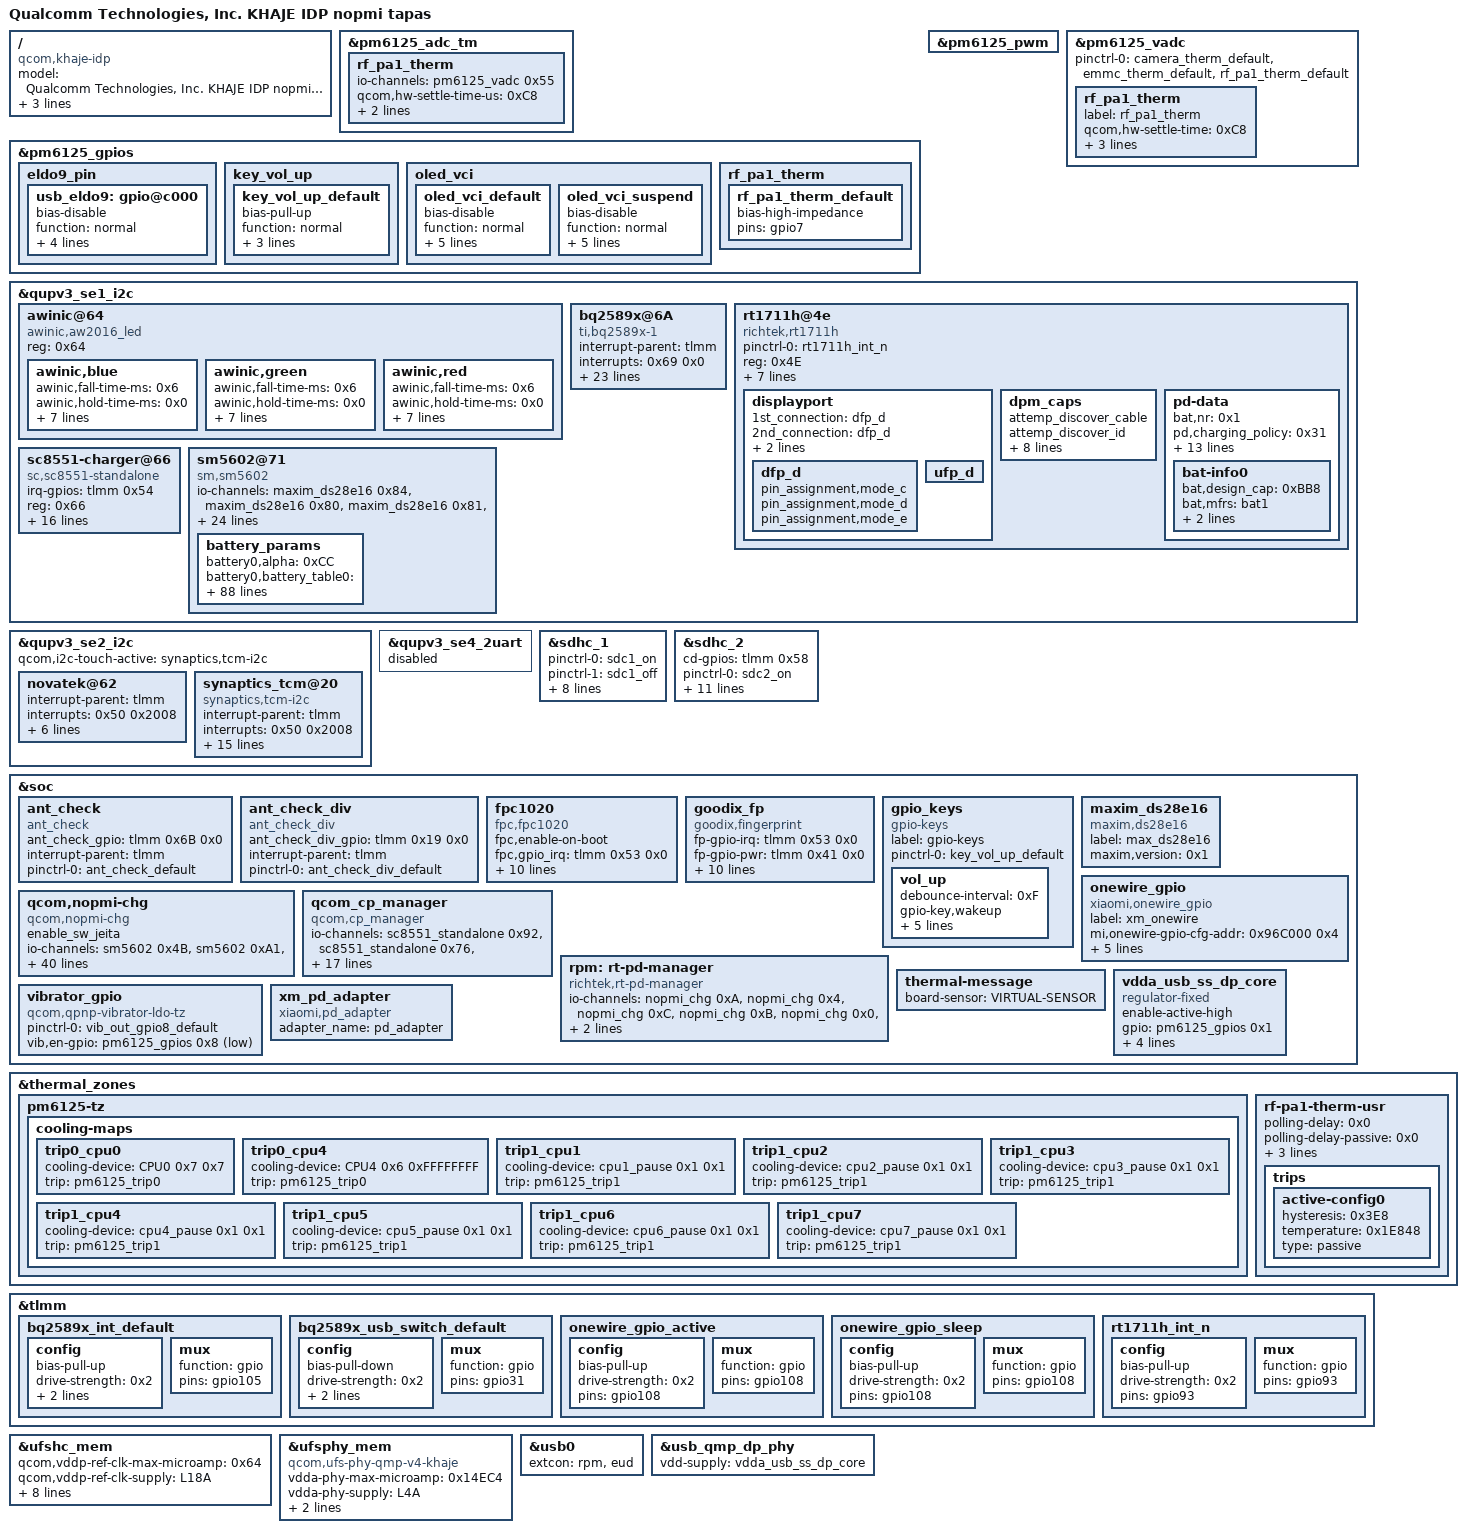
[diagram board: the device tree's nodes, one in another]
/dts-v1/;
// version: 17
// last_comp_version: 16
// boot_cpuid_phys: 0x0

/ {
    compatible = "qcom,khaje-idp", "qcom,khaje", "qcom,idp";
    model = "Qualcomm Technologies, Inc. KHAJE IDP nopmi tapas";
    qcom,board-id = <0x20022 0x0>;
    qcom,msm-id = <0x24A 0x10000>;
    qcom,pmic-id = <0x2D 0x0 0x0 0x0>;
};

&pm6125_adc_tm {
    status = "ok";
    rf_pa1_therm {
        io-channels = <&pm6125_vadc 0x55>;
        qcom,hw-settle-time-us = <0xC8>;
        qcom,ratiometric;
        reg = <0x3>;
    };
};

&pm6125_gpios {
    eldo9_pin {
        usb_eldo9: gpio@c000 {
            bias-disable;
            function = "normal";
            output-high;
            pins = "gpio1";
            power-source = <0x0>;
            qcom,drive-strength = <0x2>;
        };
    };
    key_vol_up {
        key_vol_up_default: key_vol_up_default {
            bias-pull-up;
            function = "normal";
            input-enable;
            pins = "gpio5";
            power-source = <0x0>;
        };
    };
    oled_vci {
        oled_vci_default: oled_vci_default {
            bias-disable;
            function = "normal";
            input-disable;
            output-high;
            pins = "gpio9";
            power-source = <0x0>;
            qcom,drive-strength = <0x2>;
        };
        oled_vci_suspend: oled_vci_suspend {
            bias-disable;
            function = "normal";
            input-disable;
            output-low;
            pins = "gpio9";
            power-source = <0x0>;
            qcom,drive-strength = <0x2>;
        };
    };
    rf_pa1_therm {
        rf_pa1_therm_default: rf_pa1_therm_default {
            bias-high-impedance;
            pins = "gpio7";
        };
    };
};

&pm6125_pwm {
    status = "ok";
};

&pm6125_vadc {
    pinctrl-0 = <&camera_therm_default &emmc_therm_default &rf_pa1_therm_default>;
    rf_pa1_therm {
        label = "rf_pa1_therm";
        qcom,hw-settle-time = <0xC8>;
        qcom,pre-scaling = <0x1 0x1>;
        qcom,ratiometric;
        reg = <0x55>;
    };
};

&qupv3_se1_i2c {
    #address-cells = <0x1>;
    #size-cells = <0x0>;
    status = "ok";
    awinic@64 {
        compatible = "awinic,aw2016_led";
        reg = <0x64>;
        awinic,blue {
            awinic,fall-time-ms = <0x6>;
            awinic,hold-time-ms = <0x0>;
            awinic,id = <0x2>;
            awinic,imax = <0x2>;
            awinic,led-current = <0x3>;
            awinic,max-brightness = <0xFF>;
            awinic,name = "blue";
            awinic,off-time-ms = <0x4>;
            awinic,rise-time-ms = <0x6>;
        };
        awinic,green {
            awinic,fall-time-ms = <0x6>;
            awinic,hold-time-ms = <0x0>;
            awinic,id = <0x1>;
            awinic,imax = <0x2>;
            awinic,led-current = <0x3>;
            awinic,max-brightness = <0xFF>;
            awinic,name = "green";
            awinic,off-time-ms = <0x4>;
            awinic,rise-time-ms = <0x6>;
        };
        awinic,red {
            awinic,fall-time-ms = <0x6>;
            awinic,hold-time-ms = <0x0>;
            awinic,id = <0x0>;
            awinic,imax = <0x2>;
            awinic,led-current = <0x3>;
            awinic,max-brightness = <0xFF>;
            awinic,name = "red";
            awinic,off-time-ms = <0x4>;
            awinic,rise-time-ms = <0x6>;
        };
    };
    bq2589x@6A {
        #address-cells = <0x1>;
        #io-channel-cells = <0x1>;
        #size-cells = <0x0>;
        compatible = "ti,bq2589x-1";
        interrupt-parent = <&tlmm>;
        interrupts = <0x69 0x0>;
        intr-gpio = <&tlmm 0x69 0x0>;
        io-channel-names = "ds_chip_ok", "fastcharge_mode", "fg_monitor_work", "mtbf_cur", "usb_real_type", "pd_active", "typec_cc_orientation", "typec_mode", "ffc_disable";
        io-channels = <&maxim_ds28e16 0x8D &sm5602 0xA4 &sm5602 0xAC &nopmi_chg 0x90 &nopmi_chg 0xA &nopmi_chg 0x4 &nopmi_chg 0x3 &nopmi_chg 0x1 &nopmi_chg 0xAB>;
        pinctrl-0 = <&bq2589x_int_default>;
        pinctrl-names = "default";
        reg = <0x6A>;
        ti,bq2589x,charge-current = <0x7D0>;
        ti,bq2589x,charge-current-1000 = <0x3E8>;
        ti,bq2589x,charge-current-1500 = <0x5DC>;
        ti,bq2589x,charge-current-3500 = <0xDAC>;
        ti,bq2589x,charge-current-500 = <0x1F4>;
        ti,bq2589x,charge-voltage = <0x1162>;
        ti,bq2589x,enable-auto-dpdm;
        ti,bq2589x,enable-ico;
        ti,bq2589x,enable-termination;
        ti,bq2589x,input-current-2000 = <0x7D0>;
        ti,bq2589x,term-current = <0x100>;
        ti,bq2589x,use-absolute-vindpm;
        ti,bq2589x,vbat-min-volt-to-tuneup = <0xBB8>;
        ti,bq2589x,vbus-volt-high-level = <0x21FC>;
        ti,bq2589x,vbus-volt-low-level = <0x1130>;
        usb-switch1 = <&tlmm 0x1F 0x0>;
    };
    rt1711h@4e {
        #io-channel-cells = <0x1>;
        compatible = "richtek,rt1711h";
        pinctrl-0 = <&rt1711h_int_n>;
        pinctrl-names = "default";
        reg = <0x4E>;
        rt-tcpc,name = "type_c_port0";
        rt-tcpc,role_def = <0x4>;
        rt-tcpc,rp_level = <0x0>;
        rt-tcpc,vconn_supply = <0x1>;
        rt1711pd,intr_gpio = <&tlmm 0x5D 0x0>;
        rt1711pd,intr_gpio_num = <0x5D>;
        status = "okay";
        tcpc-dual,supported_modes = <0x0>;
        displayport {
            1st_connection = "dfp_d";
            2nd_connection = "dfp_d";
            signal,dp_v13;
            typec,receptacle;
            dfp_d {
                pin_assignment,mode_c;
                pin_assignment,mode_d;
                pin_assignment,mode_e;
            };
            ufp_d {
            };
        };
        dpm_caps {
            attemp_discover_cable;
            attemp_discover_id;
            attemp_enter_dp_mode;
            dr_check = <0x0>;
            local_dr_data;
            local_dr_power;
            local_no_suspend;
            local_usb_comm;
            local_vconn_supply;
            pr_check = <0x0>;
        };
        pd-data {
            bat,nr = <0x1>;
            pd,charging_policy = <0x31>;
            pd,country_nr = <0x0>;
            pd,id-vdo-data = <0xD14029CF 0x0 0x17110000 0x61000000 0x0 0x41000000>;
            pd,id-vdo-size = <0x6>;
            pd,mfrs = "RichtekTCPC";
            pd,pid = <0x1711>;
            pd,sink-pdo-data = <0x190C8>;
            pd,sink-pdo-size = <0x1>;
            pd,source-cap-ext = [CF 29 11 17 00 00 00 00 00 00 00 00 00 00 00 00 00 00 00 00 00 00 00 02 00];
            pd,source-pdo-data = <0x19032>;
            pd,source-pdo-size = <0x1>;
            pd,vid = <0x29CF>;
            bat-info0 {
                bat,design_cap = <0xBB8>;
                bat,mfrs = "bat1";
                bat,pid = <0x1711>;
                bat,vid = <0x29CF>;
            };
        };
    };
    sc8551-charger@66 {
        #io-channel-cells = <0x1>;
        compatible = "sc,sc8551-standalone";
        irq-gpios = <&tlmm 0x54 0x0>;
        reg = <0x66>;
        sc,sc8551,ac-ovp-threshold = <0x11>;
        sc,sc8551,bat-ocp-alarm-threshold = <0x1D4C>;
        sc,sc8551,bat-ocp-threshold = <0x1F40>;
        sc,sc8551,bat-ovp-alarm-threshold = <0x1130>;
        sc,sc8551,bat-ovp-threshold = <0x11AD>;
        sc,sc8551,bat-therm-disable = <0x0>;
        sc,sc8551,bat-therm-threshold = <0x15>;
        sc,sc8551,bat-ucp-alarm-threshold = <0x7D0>;
        sc,sc8551,bus-ocp-alarm-threshold = <0xDAC>;
        sc,sc8551,bus-ocp-threshold = <0xEA6>;
        sc,sc8551,bus-ovp-alarm-threshold = <0x2AF8>;
        sc,sc8551,bus-ovp-threshold = <0x2EE0>;
        sc,sc8551,bus-therm-disable = <0x0>;
        sc,sc8551,bus-therm-threshold = <0x15>;
        sc,sc8551,die-therm-threshold = <0x7D>;
        sc,sc8551,sense-resistor-mohm = <0x5>;
    };
    sm5602@71 {
        #io-channel-cells = <0x1>;
        compatible = "sm,sm5602";
        io-channel-names = "ds_authen_result", "ds_romid", "ds_status", "ds_page0_data", "ds_chip_ok", "usb_real_type", "charging_enabled", "sc_battery_voltage", "charge_done";
        io-channels = <&maxim_ds28e16 0x84 &maxim_ds28e16 0x80 &maxim_ds28e16 0x81 &maxim_ds28e16 0x8A &maxim_ds28e16 0x8D &nopmi_chg 0xA &sc8551_standalone 0x76 &sc8551_standalone 0x96 &bq2589x 0x39>;
        reg = <0x71>;
        sm,aging_ctrl = <0x121>;
        sm,battery_table_num = <0x0>;
        sm,cycle_cfg = <0x7000>;
        sm,en_batt_det;
        sm,en_temp_ex;
        sm,fg_irq_set = <0x7FF>;
        sm,low_soc1 = <0x1>;
        sm,low_soc2 = <0xF>;
        sm,misc = <0x800>;
        sm,param_version = <0x5>;
        sm,rsns = <0x0>;
        sm,shutdown-delay-enable;
        sm,soc_decimal_rate = <0x0 0x26 0xA 0x23 0x14 0x21 0x1E 0x21 0x28 0x21 0x32 0x21 0x3C 0x21 0x46 0x1E 0x50 0x19 0x5A 0x14 0x5F 0xA>;
        sm,t_h_alarm_ex = <0x955F>;
        sm,t_h_alarm_in = <0x1>;
        sm,t_l_alarm_ex = <0xD632>;
        sm,t_l_alarm_in = <0x36>;
        sm,v_h_alarm = <0x1162>;
        sm,v_l_alarm = <0xD48>;
        battery_params {
            battery0,alpha = <0xCC>;
            battery0,battery_table0 = <0x1400 0x1B36 0x1C5B 0x1D0D 0x1D5D 0x1D7E 0x1D8D 0x1D97 0x1DC1 0x1DF0 0x1E1A 0x1E4A 0x1E6A 0x1EA2 0x1EEE 0x1F37 0x1FB9 0x2015 0x2079 0x20E8 0x219C 0x2257 0x2351 0x24CC>;
            battery0,battery_table1 = <0x0 0x66 0x1EA 0x36F 0x472 0x574 0x7FC 0xB04 0xE0D 0x1218 0x1727 0x1C35 0x2143 0x28D9 0x306E 0x357C 0x3A8B 0x3F99 0x44A7 0x49B5 0x514B 0x58E0 0x6400 0x64E6>;
            battery0,battery_table2 = <0x1620 0x1113 0xF10 0xD0E 0xC0C 0xB0B 0xA0A 0xA0A>;
            battery0,battery_type = <0x1162 0x0 0x26CC>;
            battery0,beta = <0x25>;
            battery0,curr_offset = <0x0>;
            battery0,curr_slope = <0x8088>;
            battery0,ext_temp_cal = <0x0 0x2 0x1 0x2 0x1 0x1 0x2 0x3 0x2 0x3>;
            battery0,fcm_offset = <0x40>;
            battery0,max_voltage_uv = <0x43E6D0>;
            battery0,mix_value = <0x3>;
            battery0,param_version = <0xA>;
            battery0,rs = <0x5F>;
            battery0,rs_value = <0x50 0x10A 0x3800 0x48>;
            battery0,tem_poff = <0xD48 0x64>;
            battery0,temp_cal = <0x0 0x6 0x1 0xB 0xFFFFFFFF 0x0 0x6 0x1 0x9 0x1>;
            battery0,temp_offset = <0x0 0xB 0x1 0x0 0x8 0xFFFFFFFF>;
            battery0,temp_std = <0x19>;
            battery0,thermal_table = <0x1D45 0x1A99 0x18FA 0x14E0 0x111E 0xD90 0x8B0 0x4E7 0x7A 0xF4E4 0xF21D 0xEE35 0xEAD5 0xE736 0xE3CF 0xDFEC 0xDC89 0xD9F2 0xD77F 0xD3F4 0xD13E 0xCF91 0xCC61 0xCA37 0xC81E 0xC5C3 0xC2D0 0xC069 0xBE17 0xBBE1 0xB9C6 0xB7C0 0xB5D3 0xB400 0xB242 0xB092 0xAEFD 0xAD7C 0xAC06 0xAAA6 0xA953 0xA814 0xA6DE 0xA5BE 0xA4A5 0xA39C 0xA2A1 0xA1B1 0xA0CB 0x9FF3 0x9F23 0x9E59 0x9D9A 0x9CE7 0x9C3B 0x9B95 0x9AF7 0x9A62 0x99D2 0x994B 0x98CB 0x984E 0x97D6 0x9765 0x96FA 0x9693 0x9631 0x95D3 0x9579 0x9523 0x94CF 0x9481 0x9435 0x93EC 0x93A6 0x9364 0x9325 0x92EA 0x92B1 0x927B 0x9245 0x9212 0x91E1 0x91B2 0x9185 0x915A 0x9132 0x910B 0x90E6 0x90C2 0x90A0 0x907E 0x905E 0x9040 0x9022 0x9006 0x8FEA 0x8FD0 0x8FB7 0x8FA0 0x8F8A>;
            battery0,topoff_soc = <0x7 0x15E>;
            battery0,vit_period = <0x325A>;
            battery0,volt_cal = <0x8000>;
            battery1,alpha = <0xCC>;
            battery1,battery_table0 = <0x1400 0x1B36 0x1C5B 0x1D0D 0x1D5D 0x1D7E 0x1D8D 0x1D97 0x1DC1 0x1DF0 0x1E1A 0x1E4A 0x1E6A 0x1EA2 0x1EEE 0x1F37 0x1FB9 0x2015 0x2079 0x20E8 0x219C 0x2257 0x2351 0x24CC>;
            battery1,battery_table1 = <0x0 0x66 0x1EA 0x36F 0x472 0x574 0x7FC 0xB04 0xE0D 0x1218 0x1727 0x1C35 0x2143 0x28D9 0x306E 0x357C 0x3A8B 0x3F99 0x44A7 0x49B5 0x514B 0x58E0 0x6400 0x64E6>;
            battery1,battery_table2 = <0x1620 0x1113 0xF10 0xD0E 0xC0C 0xB0B 0xA0A 0xA0A>;
            battery1,battery_type = <0x1162 0x0 0x26CC>;
            battery1,beta = <0x25>;
            battery1,curr_offset = <0x0>;
            battery1,curr_slope = <0x8088>;
            battery1,ext_temp_cal = <0x0 0x2 0x1 0x2 0x1 0x1 0x2 0x3 0x2 0x3>;
            battery1,fcm_offset = <0x40>;
            battery1,max_voltage_uv = <0x43E6D0>;
            battery1,mix_value = <0x3>;
            battery1,param_version = <0xA>;
            battery1,rs = <0x5F>;
            battery1,rs_value = <0x50 0x10A 0x3800 0x48>;
            battery1,tem_poff = <0xD48 0x64>;
            battery1,temp_cal = <0x0 0x6 0x1 0xB 0xFFFFFFFF 0x0 0x6 0x1 0x9 0x1>;
            battery1,temp_offset = <0x0 0xB 0x1 0x0 0x8 0xFFFFFFFF>;
            battery1,temp_std = <0x19>;
            battery1,thermal_table = <0x1D45 0x1A99 0x18FA 0x14E0 0x111E 0xD90 0x8B0 0x4E7 0x7A 0xF4E4 0xF21D 0xEE35 0xEAD5 0xE736 0xE3CF 0xDFEC 0xDC89 0xD9F2 0xD77F 0xD3F4 0xD13E 0xCF91 0xCC61 0xCA37 0xC81E 0xC5C3 0xC2D0 0xC069 0xBE17 0xBBE1 0xB9C6 0xB7C0 0xB5D3 0xB400 0xB242 0xB092 0xAEFD 0xAD7C 0xAC06 0xAAA6 0xA953 0xA814 0xA6DE 0xA5BE 0xA4A5 0xA39C 0xA2A1 0xA1B1 0xA0CB 0x9FF3 0x9F23 0x9E59 0x9D9A 0x9CE7 0x9C3B 0x9B95 0x9AF7 0x9A62 0x99D2 0x994B 0x98CB 0x984E 0x97D6 0x9765 0x96FA 0x9693 0x9631 0x95D3 0x9579 0x9523 0x94CF 0x9481 0x9435 0x93EC 0x93A6 0x9364 0x9325 0x92EA 0x92B1 0x927B 0x9245 0x9212 0x91E1 0x91B2 0x9185 0x915A 0x9132 0x910B 0x90E6 0x90C2 0x90A0 0x907E 0x905E 0x9040 0x9022 0x9006 0x8FEA 0x8FD0 0x8FB7 0x8FA0 0x8F8A>;
            battery1,topoff_soc = <0x7 0x15E>;
            battery1,vit_period = <0x325A>;
            battery1,volt_cal = <0x8000>;
            battery2,alpha = <0xCC>;
            battery2,battery_table0 = <0x1400 0x1B48 0x1C6F 0x1CEE 0x1D4A 0x1D7D 0x1D8D 0x1D9B 0x1DCD 0x1E03 0x1E2E 0x1E5C 0x1E7B 0x1E9F 0x1EE9 0x1F2F 0x1FB6 0x2010 0x2073 0x20E1 0x2194 0x2254 0x2351 0x24CC>;
            battery2,battery_table1 = <0x0 0x65 0x1ED 0x2F3 0x3F8 0x4FE 0x709 0xB1F 0xEB2 0x13CE 0x18E9 0x1E05 0x2321 0x283C 0x2FE6 0x3501 0x3A1D 0x3F39 0x4454 0x4970 0x5119 0x58C3 0x6400 0x64E6>;
            battery2,battery_table2 = <0x1620 0x1113 0xF10 0xD0E 0xC0C 0xB0B 0xA0A 0xA0A>;
            battery2,battery_type = <0x1162 0x0 0x2699>;
            battery2,beta = <0x25>;
            battery2,curr_offset = <0x0>;
            battery2,curr_slope = <0x8088>;
            battery2,ext_temp_cal = <0x0 0x2 0x1 0x2 0x1 0x1 0x2 0x3 0x2 0x3>;
            battery2,fcm_offset = <0x40>;
            battery2,max_voltage_uv = <0x43E6D0>;
            battery2,mix_value = <0x3>;
            battery2,param_version = <0xA>;
            battery2,rs = <0x5F>;
            battery2,rs_value = <0x50 0x10A 0x3800 0x48>;
            battery2,tem_poff = <0xD48 0x64>;
            battery2,temp_cal = <0x0 0x6 0x1 0xB 0xFFFFFFFF 0x0 0x6 0x1 0x9 0x1>;
            battery2,temp_offset = <0x0 0xB 0x1 0x0 0x8 0xFFFFFFFF>;
            battery2,temp_std = <0x19>;
            battery2,thermal_table = <0x1D45 0x1A99 0x18FA 0x14E0 0x111E 0xD90 0x8B0 0x4E7 0x7A 0xF4E4 0xF21D 0xEE35 0xEAD5 0xE736 0xE3CF 0xDFEC 0xDC89 0xD9F2 0xD77F 0xD3F4 0xD13E 0xCF91 0xCC61 0xCA37 0xC81E 0xC5C3 0xC2D0 0xC069 0xBE17 0xBBE1 0xB9C6 0xB7C0 0xB5D3 0xB400 0xB242 0xB092 0xAEFD 0xAD7C 0xAC06 0xAAA6 0xA953 0xA814 0xA6DE 0xA5BE 0xA4A5 0xA39C 0xA2A1 0xA1B1 0xA0CB 0x9FF3 0x9F23 0x9E59 0x9D9A 0x9CE7 0x9C3B 0x9B95 0x9AF7 0x9A62 0x99D2 0x994B 0x98CB 0x984E 0x97D6 0x9765 0x96FA 0x9693 0x9631 0x95D3 0x9579 0x9523 0x94CF 0x9481 0x9435 0x93EC 0x93A6 0x9364 0x9325 0x92EA 0x92B1 0x927B 0x9245 0x9212 0x91E1 0x91B2 0x9185 0x915A 0x9132 0x910B 0x90E6 0x90C2 0x90A0 0x907E 0x905E 0x9040 0x9022 0x9006 0x8FEA 0x8FD0 0x8FB7 0x8FA0 0x8F8A>;
            battery2,topoff_soc = <0x7 0x15E>;
            battery2,vit_period = <0x325A>;
            battery2,volt_cal = <0x8000>;
        };
    };
};

&qupv3_se2_i2c {
    qcom,i2c-touch-active = "synaptics,tcm-i2c";
    status = "okay";
    novatek@62 {
        interrupt-parent = <&tlmm>;
        interrupts = <0x50 0x2008>;
        novatek,irq-gpio = <&tlmm 0x50 0x2008>;
        novatek,reset-gpio = <&tlmm 0x56 0x0>;
        pinctrl-0 = <&ts_int_active &ts_reset_active>;
        pinctrl-1 = <&ts_int_suspend &ts_reset_suspend>;
        pinctrl-2 = <&ts_release>;
        pinctrl-names = "pmx_ts_active", "pmx_ts_suspend", "pmx_ts_release";
        reg = <0x62>;
        status = "ok";
    };
    synaptics_tcm@20 {
        compatible = "synaptics,tcm-i2c";
        interrupt-parent = <&tlmm>;
        interrupts = <0x50 0x2008>;
        pinctrl-0 = <&ts_int_active &ts_reset_active>;
        pinctrl-1 = <&ts_int_suspend &ts_reset_suspend>;
        pinctrl-2 = <&ts_release>;
        pinctrl-names = "pmx_ts_active", "pmx_ts_suspend", "pmx_ts_release";
        reg = <0x20>;
        synaptics,extend_report;
        synaptics,firmware-name = "synaptics_firmware_k.img";
        synaptics,irq-gpio = <&tlmm 0x50 0x2008>;
        synaptics,irq-on-state = <0x0>;
        synaptics,power-delay-ms = <0xC8>;
        synaptics,reset-active-ms = <0x14>;
        synaptics,reset-delay-ms = <0xC8>;
        synaptics,reset-gpio = <&tlmm 0x56 0x0>;
        synaptics,reset-on-state = <0x0>;
        synaptics,ubl-i2c-addr = <0x20>;
    };
};

&qupv3_se4_2uart {
    status = "disabled";
};

&sdhc_1 {
    pinctrl-0 = <&sdc1_on>;
    pinctrl-1 = <&sdc1_off>;
    pinctrl-names = "default", "sleep";
    qcom,vdd-current-level = <0x0 0x8B290>;
    qcom,vdd-io-always-on;
    qcom,vdd-io-current-level = <0x0 0x4F588>;
    qcom,vdd-io-lpm-sup;
    qcom,vdd-io-voltage-level = <0x1B7740 0x1B7740>;
    qcom,vdd-voltage-level = <0x2D2A80 0x2D2A80>;
    status = "ok";
    vdd-io-supply = <&L11A>;
    vdd-supply = <&L24A>;
};

&sdhc_2 {
    cd-gpios = <&tlmm 0x58 0x0>;
    pinctrl-0 = <&sdc2_on>;
    pinctrl-1 = <&sdc2_off>;
    pinctrl-names = "default", "sleep";
    qcom,vdd-current-level = <0x0 0xC3500>;
    qcom,vdd-io-bias-current-level = <0x0 0x1770>;
    qcom,vdd-io-bias-voltage-level = <0x132A40 0x132A40>;
    qcom,vdd-io-current-level = <0x0 0x55F0>;
    qcom,vdd-io-voltage-level = <0x1B7740 0x2D2A80>;
    qcom,vdd-voltage-level = <0x2D2A80 0x2D2A80>;
    status = "ok";
    vdd-io-bias-supply = <&L7A>;
    vdd-io-supply = <&L5A>;
    vdd-supply = <&L22A>;
};

&soc {
    ant_check {
        ant_check_gpio = <&tlmm 0x6B 0x0>;
        compatible = "ant_check";
        interrupt-parent = <&tlmm>;
        pinctrl-0 = <&ant_check_default>;
        pinctrl-names = "default";
    };
    ant_check_div {
        ant_check_div_gpio = <&tlmm 0x19 0x0>;
        compatible = "ant_check_div";
        interrupt-parent = <&tlmm>;
        pinctrl-0 = <&ant_check_div_default>;
        pinctrl-names = "default";
    };
    fpc1020 {
        compatible = "fpc,fpc1020";
        fpc,enable-on-boot;
        fpc,gpio_irq = <&tlmm 0x53 0x0>;
        fpc,gpio_rst = <&tlmm 0x68 0x0>;
        fpc,gpio_vdd_for_plsensor = <&tlmm 0x41 0x0>;
        interrupt-parent = <&tlmm>;
        interrupts = <0x53 0x0>;
        pinctrl-0 = <&msm_gpio_104>;
        pinctrl-1 = <&msm_gpio_104_output_high>;
        pinctrl-2 = <&msm_gpio_83>;
        pinctrl-names = "fpc1020_reset_reset", "fpc1020_reset_active", "fpc1020_irq_active";
        status = "ok";
        vcc_spi-supply = <&pm6125_l9>;
        vdd_ana-supply = <&pm6125_l9>;
        vdd_io-supply = <&pm6125_l9>;
    };
    goodix_fp {
        compatible = "goodix,fingerprint";
        fp-gpio-irq = <&tlmm 0x53 0x0>;
        fp-gpio-pwr = <&tlmm 0x41 0x0>;
        fp-gpio-reset = <&tlmm 0x68 0x0>;
        interrupt = <0x53 0x0>;
        interrupt-parent = <&tlmm>;
        pinctrl-0 = <&msm_gpio_104>;
        pinctrl-1 = <&msm_gpio_104_output_high>;
        pinctrl-2 = <&msm_gpio_65>;
        pinctrl-3 = <&msm_gpio_65_output_high>;
        pinctrl-names = "goodix_reset_outputlow", "goodix_reset_outputhigh", "goodix_pwr_outputlow", "goodix_pwr_outputhigh";
        status = "okay";
        vcc_ana_supply = <&pm6125_l9>;
        vcc_spi_supply = <&pm6125_l9>;
        vdd_io-supply = <&pm6125_l9>;
    };
    gpio_keys {
        compatible = "gpio-keys";
        label = "gpio-keys";
        pinctrl-0 = <&key_vol_up_default>;
        pinctrl-names = "default";
        vol_up {
            debounce-interval = <0xF>;
            gpio-key,wakeup;
            gpios = <&pm6125_gpios 0x5 0x1>;
            label = "volume_up";
            linux,can-disable;
            linux,code = <0x73>;
            linux,input-type = <0x1>;
        };
    };
    maxim_ds28e16 {
        #io-channel-cells = <0x1>;
        compatible = "maxim,ds28e16";
        label = "max_ds28e16";
        maxim,version = <0x1>;
        status = "ok";
    };
    onewire_gpio {
        compatible = "xiaomi,onewire_gpio";
        label = "xm_onewire";
        mi,onewire-gpio-cfg-addr = <0x96C000 0x4>;
        pinctrl-0 = <&onewire_gpio_active>;
        pinctrl-1 = <&onewire_gpio_sleep>;
        pinctrl-names = "onewire_active", "onewire_sleep";
        status = "ok";
        xiaomi,gpio_number = <0x6C>;
        xiaomi,ow_gpio = <&tlmm 0x6C 0x0>;
        xiaomi,version = <0x1>;
    };
    qcom,nopmi-chg {
        #io-channel-cells = <0x1>;
        compatible = "qcom,nopmi-chg";
        enable_sw_jeita;
        io-channel-names = "resistance_id", "shutdown_delay", "soc_decimal", "soc_decimal_rate", "fastcharge_mode", "fg_batt_id", "charge_type", "charge_enabled", "charge_ic_type", "charge_pd_active", "sc_bus_current", "charging_enabled", "sc_chip_id", "cc_chip_id", "ds_chip_id", "ds_chip_ok", "ds_authen_result";
        io-channels = <&sm5602 0x4B &sm5602 0xA1 &sm5602 0xA2 &sm5602 0xA3 &sm5602 0xA4 &sm5602 0xAD &bq2589x 0x74 &bq2589x 0xA0 &bq2589x 0xAA &bq2589x 0x4 &sc8551_standalone 0x9A &sc8551_standalone 0x76 &sc8551_standalone 0xA7 &rpm 0xA7 &maxim_ds28e16 0xA7 &maxim_ds28e16 0x8D &maxim_ds28e16 0x84>;
        jeita_temp_above_t4_cv = <0x1004>;
        jeita_temp_below_t0_cv = <0x1162>;
        jeita_temp_t0_to_t1_cv = <0x1162>;
        jeita_temp_t1_to_t1p5_cv = <0x1162>;
        jeita_temp_t1p5_to_t2_cv = <0x1162>;
        jeita_temp_t2_to_t3_cv = <0x1162>;
        jeita_temp_t3_to_t4_cv = <0x1004>;
        jeita_temp_tn1_to_t0_cv = <0x1162>;
        nopmi,thermal-mitigation = <0x5ACA30 0x5265C0 0x4C4B40 0x44AA20 0x3D0900 0x387520 0x3567E0 0x2DC6C0 0x2AB980 0x2625A0 0x1E8480 0x16E360 0xF4240 0xC3500 0x7A120 0x493E0>;
        qcom,fv-max-uv = <0x432380>;
        status = "okay";
        temp_neg_10_thres = <0xFFFFFFF6>;
        temp_t0_thres = <0x0>;
        temp_t0_thres_plus_x_degree = <0x1>;
        temp_t0_to_t1_fcc = <0x3B6>;
        temp_t1_thres = <0x5>;
        temp_t1_thres_plus_x_degree = <0x6>;
        temp_t1_to_t1p5_fcc = <0x960>;
        temp_t1p5_thres = <0xA>;
        temp_t1p5_thres_plus_x_degree = <0xB>;
        temp_t1p5_to_t2_fcc = <0xF3C>;
        temp_t2_thres = <0xF>;
        temp_t2_thres_plus_x_degree = <0x11>;
        temp_t2_to_t3_fcc = <0x173E>;
        temp_t3_thres = <0x30>;
        temp_t3_thres_minus_x_degree = <0x2E>;
        temp_t3_to_t4_fcc = <0x92E>;
        temp_t4_thres = <0x3C>;
        temp_t4_thres_minus_x_degree = <0x3A>;
        temp_tn1_thres = <0xFFFFFFF6>;
        temp_tn1_thres_plus_x_degree = <0xFFFFFFF7>;
        temp_tn1_to_t0_fcc = <0x1EA>;
    };
    qcom_cp_manager {
        compatible = "qcom,cp_manager";
        io-channel-names = "present", "charging_enabled", "status", "sc_battery_present", "sc_vbus_present", "sc_battery_voltage", "sc_battery_current", "sc_battery_temperature", "sc_bus_voltage", "sc_bus_current", "sc_bus_temperature", "sc_die_temperature", "sc_alarm_status", "sc_fault_status", "sc_vbus_error_status", "sc_chip_vendor", "sc_chip_id", "input_suspend", "pd_active", "battery_charging_enabled", "charge_enabled", "apdo_volt", "apdo_curr";
        io-channels = <&sc8551_standalone 0x92 &sc8551_standalone 0x76 &sc8551_standalone 0x91 &sc8551_standalone 0x94 &sc8551_standalone 0x95 &sc8551_standalone 0x96 &sc8551_standalone 0x97 &sc8551_standalone 0x98 &sc8551_standalone 0x99 &sc8551_standalone 0x9A &sc8551_standalone 0x9B &sc8551_standalone 0x9C &sc8551_standalone 0x9D &sc8551_standalone 0x93 &sc8551_standalone 0x9E &sc8551_standalone 0x9F &sc8551_standalone 0xA7 &nopmi_chg 0x78 &nopmi_chg 0x4 &nopmi_chg 0x76 &bq2589x 0xA0 &nopmi_chg 0xA8 &nopmi_chg 0xA9>;
        status = "okay";
    };
    rpm: rt-pd-manager {
        #io-channel-cells = <0x1>;
        compatible = "richtek,rt-pd-manager";
        io-channel-names = "usb_real_type", "pd_active", "pd_voltage_min", "pd_voltage_max", "pd_current_max", "typec_cc_orientation", "pd_usb_suspend_supported", "pd_in_hard_reset", "cc_chip_id";
        io-channels = <&nopmi_chg 0xA &nopmi_chg 0x4 &nopmi_chg 0xC &nopmi_chg 0xB &nopmi_chg 0x0 &nopmi_chg 0x3 &nopmi_chg 0x1F &nopmi_chg 0x1E &rpm 0xA7>;
    };
    thermal-message {
        board-sensor = "VIRTUAL-SENSOR";
    };
    vdda_usb_ss_dp_core {
        compatible = "regulator-fixed";
        enable-active-high;
        gpio = <&pm6125_gpios 0x1 0x0>;
        pinctrl-0 = <&usb_eldo9>;
        pinctrl-names = "default";
        regulator-max-microvolt = <0xD6D80>;
        regulator-min-microvolt = <0xD6D80>;
        regulator-name = "vdd_supply";
    };
    vibrator_gpio {
        compatible = "qcom,qpnp-vibrator-ldo-tz";
        pinctrl-0 = <&vib_out_gpio8_default>;
        pinctrl-names = "default";
        status = "ok";
        vib,en-gpio = <&pm6125_gpios 0x8 0x1>;
    };
    xm_pd_adapter {
        adapter_name = "pd_adapter";
        compatible = "xiaomi,pd_adapter";
    };
};

&thermal_zones {
    pm6125-tz {
        cooling-maps {
            trip0_cpu0 {
                cooling-device = <&CPU0 0x7 0x7>;
                trip = <&pm6125_trip0>;
            };
            trip0_cpu4 {
                cooling-device = <&CPU4 0x6 0xFFFFFFFF>;
                trip = <&pm6125_trip0>;
            };
            trip1_cpu1 {
                cooling-device = <&cpu1_pause 0x1 0x1>;
                trip = <&pm6125_trip1>;
            };
            trip1_cpu2 {
                cooling-device = <&cpu2_pause 0x1 0x1>;
                trip = <&pm6125_trip1>;
            };
            trip1_cpu3 {
                cooling-device = <&cpu3_pause 0x1 0x1>;
                trip = <&pm6125_trip1>;
            };
            trip1_cpu4 {
                cooling-device = <&cpu4_pause 0x1 0x1>;
                trip = <&pm6125_trip1>;
            };
            trip1_cpu5 {
                cooling-device = <&cpu5_pause 0x1 0x1>;
                trip = <&pm6125_trip1>;
            };
            trip1_cpu6 {
                cooling-device = <&cpu6_pause 0x1 0x1>;
                trip = <&pm6125_trip1>;
            };
            trip1_cpu7 {
                cooling-device = <&cpu7_pause 0x1 0x1>;
                trip = <&pm6125_trip1>;
            };
        };
    };
    rf-pa1-therm-usr {
        polling-delay = <0x0>;
        polling-delay-passive = <0x0>;
        thermal-governor = "user_space";
        thermal-sensors = <&pm6125_adc_tm 0x3>;
        wake-capable-sensor;
        trips {
            active-config0 {
                hysteresis = <0x3E8>;
                temperature = <0x1E848>;
                type = "passive";
            };
        };
    };
};

&tlmm {
    bq2589x_int_default {
        config {
            bias-pull-up;
            drive-strength = <0x2>;
            input-enable;
            pins = "gpio105";
        };
        mux {
            function = "gpio";
            pins = "gpio105";
        };
    };
    bq2589x_usb_switch_default {
        config {
            bias-pull-down;
            drive-strength = <0x2>;
            output-low;
            pins = "gpio31";
        };
        mux {
            function = "gpio";
            pins = "gpio31";
        };
    };
    onewire_gpio_active {
        config {
            bias-pull-up;
            drive-strength = <0x2>;
            pins = "gpio108";
        };
        mux {
            function = "gpio";
            pins = "gpio108";
        };
    };
    onewire_gpio_sleep {
        config {
            bias-pull-up;
            drive-strength = <0x2>;
            pins = "gpio108";
        };
        mux {
            function = "gpio";
            pins = "gpio108";
        };
    };
    rt1711h_int_n: rt1711h_int_n {
        config {
            bias-pull-up;
            drive-strength = <0x2>;
            pins = "gpio93";
        };
        mux {
            function = "gpio";
            pins = "gpio93";
        };
    };
};

&ufshc_mem {
    qcom,vddp-ref-clk-max-microamp = <0x64>;
    qcom,vddp-ref-clk-supply = <&L18A>;
    reset-gpios = <&tlmm 0x71 0x1>;
    reset-names = "rst";
    resets = <&gcc 0x4>;
    status = "ok";
    vcc-max-microamp = <0xC3500>;
    vcc-supply = <&L24A>;
    vccq2-max-microamp = <0xC3500>;
    vccq2-supply = <&L11A>;
    vdd-hba-fixed-regulator;
    vdd-hba-supply = <&gcc_ufs_phy_gdsc>;
};

&ufsphy_mem {
    compatible = "qcom,ufs-phy-qmp-v4-khaje";
    status = "ok";
    vdda-phy-max-microamp = <0x14EC4>;
    vdda-phy-supply = <&L4A>;
    vdda-pll-max-microamp = <0x477C>;
    vdda-pll-supply = <&L18A>;
};

&usb0 {
    extcon = <&rpm &eud>;
};

&usb_qmp_dp_phy {
    vdd-supply = <&vdda_usb_ss_dp_core>;
};

